# K210 register map
Vendor: Canaan Inc.; File version: 1.0
Kendryte K210 64-bit RISC-V CPU
Registers are 32-bit, read-write, reset 0x0 unless marked. A register's access mark holds for its fields unless they carry their own. Offsets are from the block's base; lines under a group give offsets from that group; [hi:lo] are bit positions; {n}, {i} and the like mark numbered series; 'fields as' and 'values as' point back to an identical list; <NAME> marks a mode.

## Memory map
0x02000000 CLINT — Core Local Interruptor
0x0C000000 PLIC — Platform-Level Interrupt Controller
0x38000000 UARTHS — High-speed UART
0x38001000 GPIOHS — High-speed GPIO
0x40800000 KPU — Neural Network Accelerator
0x42000000 FFT — Fast Fourier Transform Accelerator
0x50000000 DMAC — Direct Memory Access Controller
0x50200000 GPIO — General Purpose Input/Output Interface
0x50210000 UART1 — Universal Asynchronous Receiver-Transmitter 1
0x50220000 UART2 — Universal Asynchronous Receiver-Transmitter 2
0x50230000 UART3 — Universal Asynchronous Receiver-Transmitter 3
0x50240000 SPI2 — Serial Peripheral Interface 2 (slave)
0x50250000 I2S0 — Inter-Integrated Sound Interface 0
0x50250200 APU — Audio Processor
0x50260000 I2S1 — Inter-Integrated Sound Interface 1
0x50270000 I2S2 — Inter-Integrated Sound Interface 2
0x50280000 I2C0 — Inter-Integrated Circuit Bus 0
0x50290000 I2C1 — Inter-Integrated Circuit Bus 1
0x502A0000 I2C2 — Inter-Integrated Circuit Bus 2
0x502B0000 FPIOA — Field Programmable IO Array
0x502C0000 SHA256 — SHA256 Accelerator
0x502D0000 TIMER0
0x502E0000 TIMER1
0x502F0000 TIMER2
0x50400000 WDT0 — Watchdog Timer 0
0x50410000 WDT1 — Watchdog Timer 1
0x50420000 OTP — One-Time Programmable Memory Controller
0x50430000 DVP — Digital Video Port
0x50440000 SYSCTL — System Controller
0x50450000 AES — AES Accelerator
0x50460000 RTC — Real Time Clock
0x52000000 SPI0 — Serial Peripheral Interface 0 (master)
0x53000000 SPI1 — Serial Peripheral Interface 1 (master)
0x54000000 SPI3 — Serial Peripheral Interface 3 (master)

## Interrupts
1 SPI0
2 SPI1
3 SPI_SLAVE (SPI2)
4 SPI3
5 I2S0
6 I2S1
7 I2S2
8 I2C0
9 I2C1
10 I2C2
11 UART1
12 UART2
13 UART3
14 TIMER0A (TIMER0) — TIMER0 channel 0 or 1 interrupt
15 TIMER0B (TIMER0) — TIMER0 channel 2 or 3 interrupt
16 TIMER1A (TIMER1) — TIMER1 channel 0 or 1 interrupt
17 TIMER1B (TIMER1) — TIMER1 channel 2 or 3 interrupt
18 TIMER2A (TIMER2) — TIMER2 channel 0 or 1 interrupt
19 TIMER2B (TIMER2) — TIMER2 channel 2 or 3 interrupt
20 RTC
21 WDT0
22 WDT1
23 APB_GPIO (GPIO)
24 DVP
25 KPU
26 FFT
27 DMA0 (DMAC)
28 DMA1 (DMAC)
29 DMA2 (DMAC)
30 DMA3 (DMAC)
31 DMA4 (DMAC)
32 DMA5 (DMAC)
33 UARTHS
{n+34} GPIOHS{n} (GPIOHS) (n=0..31)

## CLINT — Core Local Interruptor
Base 0x02000000
{0x0+4i} msip[{i}] (i=0..1) range 0..1 — Hart software interrupt register
{0x4000+8i} mtimecmp[{i}] (i=0..1) 64-bit (reset mask 0xFFFFFFFF) — Hart time comparator register
0xBFF8 mtime 64-bit (reset mask 0xFFFFFFFF) — Timer register

## PLIC — Platform-Level Interrupt Controller
Base 0x0C000000
{0x0+4i} priority[{i}] (i=0..1023) — Interrupt Source Priority Register
{0x1000+4i} pending[{i}] (i=0..31) — Interrupt Pending Register
{0x2000+0x80*i} target_enables[{i}] (i=0..3) group — Target Interrupt Enables
  {0x0+4j} enable[{j}] (j=0..31) — Interrupt Enable Register
{0x200000+0x1000*i} targets[{i}] (i=0..3) group — Target Configuration
  0x00 threshold — Priority Threshold Register
    [2:0] priority
      0=Never interrupt; {v}=P{v} (Priority {v}) (v=1..7)
  0x04 claim — Claim/Complete Register
  0xFFC _reserved — Padding to make sure targets is an array

## UARTHS — High-speed UART
Base 0x38000000
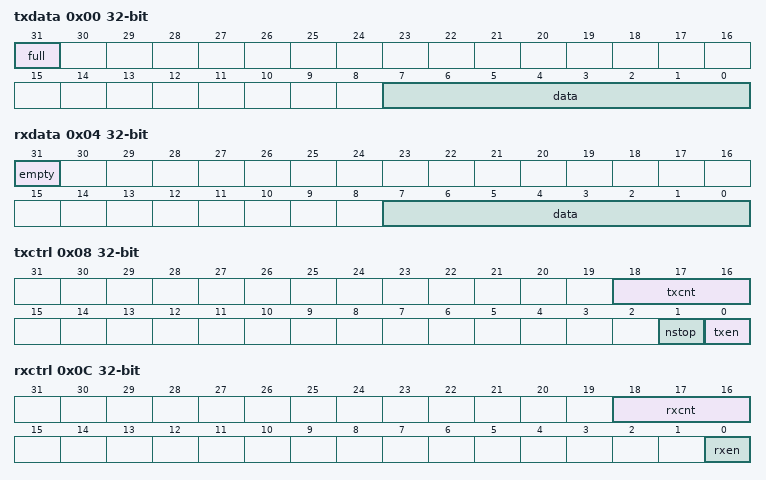
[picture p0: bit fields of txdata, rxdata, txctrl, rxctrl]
0x00 txdata — Transmit Data Register
  [31] full — Transmit FIFO full
  [7:0] data — Transmit data
0x04 rxdata — Receive Data Register
  [31] empty — Receive FIFO empty
  [7:0] data — Received data
0x08 txctrl — Transmit Control Register
  [18:16] txcnt — Transmit watermark level
  [1] nstop — Number of stop bits
  [0] txen — Transmit enable
0x0C rxctrl — Receive Control Register
  [18:16] rxcnt — Receive watermark level
  [0] rxen — Receive enable
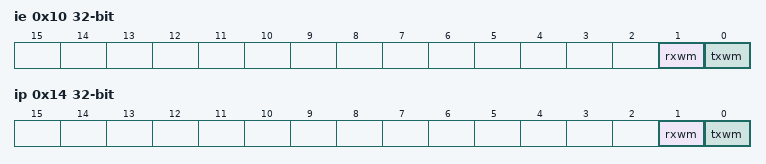
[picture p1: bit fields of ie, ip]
0x10 ie — Interrupt Enable Register
  [1] rxwm — Receive watermark interrupt enable
  [0] txwm — Transmit watermark interrupt enable
0x14 ip — Interrupt Pending Register
  [1] rxwm — Receive watermark interrupt pending
  [0] txwm — Transmit watermark interrupt pending
0x18 div — Baud Rate Divisor Register
  [15:0] div — Baud rate divisor
